# PIC18LF4620 register map
Vendor: Microchip
Architecture 18xxxx. Special function registers and configuration words.
Registers are 8-bit, read-write, no defined reset value unless marked. A register's access mark holds for its fields unless they carry their own. Addresses are absolute, and some are shared; only a register's first bit layout is shown; lines under a group give offsets from that group; [hi:lo] are bit positions; {n}, {i} and the like mark numbered series; 'fields as' and 'values as' point back to an identical list; <NAME> marks a mode.

## Further device data
pins=1: MCLR/VPP/RE3; 2: RA0/AN0; 3: RA1/AN1; 4: RA2/AN2/VREF-/CVREF; 5: RA3/AN3/VREF+; 6: RA4/T0CKI/C1OUT; 7: RA5/AN4/SS/HLVDIN/C2OUT; 8: RE0/RD/AN5; 9: RE1/WR/AN6; 10: RE2/CS/AN7; 11: VDD; 12: VSS; 13: OSC1/CLKI/RA7; 14: OSC2/CLKO/RA6; 15: RC0/T1OSO/T13CKI; 16: RC1/T1OSI/CCP2; 17: RC2/CCP1/P1A; 18: RC3/SCK/SCL; 19: RD0/PSP0; 20: RD1/PSP1; 21: RD2/PSP2; 22: RD3/PSP3; 23: RC4/SDI/SDA; 24: RC5/SDO; 25: RC6/TX/CK; 26: RC7/RX/DT; 27: RD4/PSP4; 28: RD5/PSP5/P1B; 29: RD6/PSP6/P1C; 30: RD7/PSP7/P1D; 31: RB0/INT0/FLT0/AN12; 32: RB1/INT1/AN10; 33: RB2/INT2/AN8; 34: RB3/AN9/CCP2; 35: RB4/KBI0/AN11; 36: RB5/KBI1/PGM; 37: RB6/KBI2/PGC; 38: RB7/KBI3/PGD

## SFR
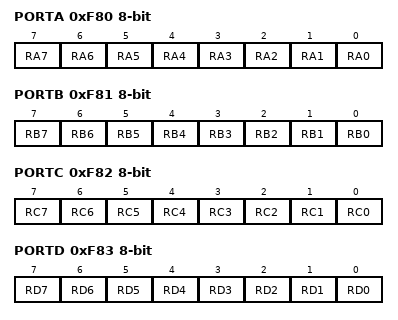
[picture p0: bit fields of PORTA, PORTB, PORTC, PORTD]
0xF80 PORTA — (power-on value xx0x0000)
  [n] RA{n} (n=0..7)
0xF81 PORTB — (power-on value xxxxxxxx)
  [n] RB{n} (n=0..7)
0xF82 PORTC — (power-on value xxxxxxxx)
  [n] RC{n} (n=0..7)
0xF83 PORTD — (power-on value xxxxxxxx)
  [n] RD{n} (n=0..7)
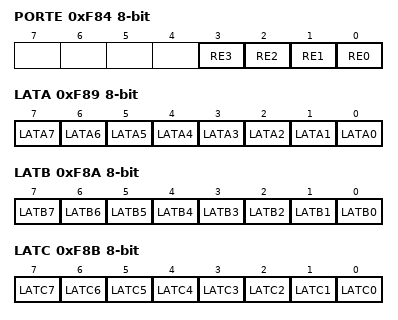
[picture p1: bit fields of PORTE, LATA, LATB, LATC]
0xF84 PORTE — (power-on value ----xxxx)
  [3] RE3 ro, [2] RE2, [1] RE1, [0] RE0
0xF89 LATA — (power-on value xxxxxxxx)
  [n] LATA{n} (n=0..7)
0xF8A LATB — (power-on value xxxxxxxx)
  [n] LATB{n} (n=0..7)
0xF8B LATC — (power-on value xxxxxxxx)
  [n] LATC{n} (n=0..7)
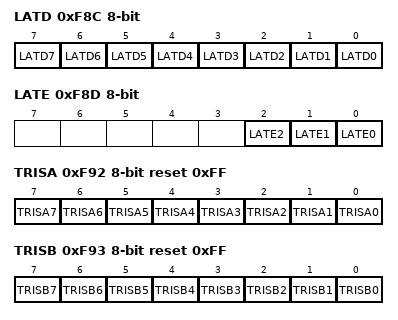
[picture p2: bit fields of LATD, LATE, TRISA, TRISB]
0xF8C LATD — (power-on value xxxxxxxx)
  [n] LATD{n} (n=0..7)
0xF8D LATE — (power-on value -----xxx)
  [2] LATE2, [1] LATE1, [0] LATE0
0xF92 TRISA reset 0xFF
  [n] TRISA{n} (n=0..7)
0xF93 TRISB reset 0xFF
  [n] TRISB{n} (n=0..7)
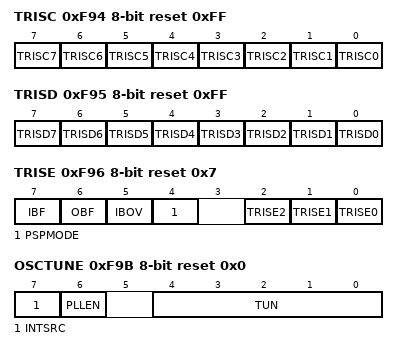
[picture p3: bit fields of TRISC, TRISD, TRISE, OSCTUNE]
0xF94 TRISC reset 0xFF
  [n] TRISC{n} (n=0..7)
0xF95 TRISD reset 0xFF
  [n] TRISD{n} (n=0..7)
0xF96 TRISE reset 0x7
  [7] IBF, [6] OBF, [5] IBOV, [4] PSPMODE, [2] TRISE2, [1] TRISE1, [0] TRISE0
0xF9B OSCTUNE reset 0x0
  [7] INTSRC, [6] PLLEN, [4:0] TUN
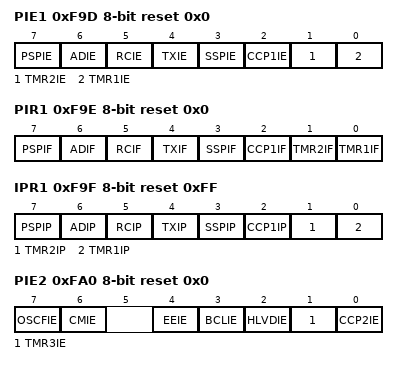
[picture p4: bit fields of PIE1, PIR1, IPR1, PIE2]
0xF9D PIE1 reset 0x0
  [7] PSPIE, [6] ADIE, [5] RCIE, [4] TXIE, [3] SSPIE, [2] CCP1IE, [1] TMR2IE, [0] TMR1IE
0xF9E PIR1 reset 0x0
  [7] PSPIF, [6] ADIF, [5] RCIF ro, [4] TXIF ro, [3] SSPIF, [2] CCP1IF, [1] TMR2IF, [0] TMR1IF
0xF9F IPR1 reset 0xFF
  [7] PSPIP, [6] ADIP, [5] RCIP, [4] TXIP, [3] SSPIP, [2] CCP1IP, [1] TMR2IP, [0] TMR1IP
0xFA0 PIE2 reset 0x0
  [7] OSCFIE, [6] CMIE, [4] EEIE, [3] BCLIE, [2] HLVDIE, [1] TMR3IE, [0] CCP2IE
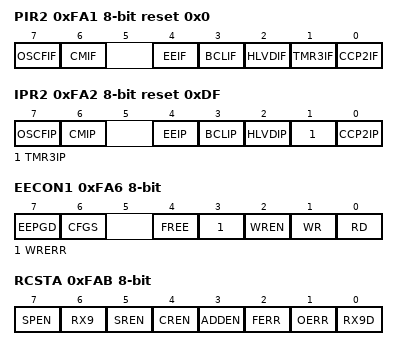
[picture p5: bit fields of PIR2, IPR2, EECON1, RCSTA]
0xFA1 PIR2 reset 0x0
  [7] OSCFIF, [6] CMIF, [4] EEIF, [3] BCLIF, [2] HLVDIF, [1] TMR3IF, [0] CCP2IF
0xFA2 IPR2 reset 0xDF
  [7] OSCFIP, [6] CMIP, [4] EEIP, [3] BCLIP, [2] HLVDIP, [1] TMR3IP, [0] CCP2IP
0xFA6 EECON1 — (power-on value xx-0x000)
  [7] EEPGD
  [6] CFGS
  [4] FREE
  [3] WRERR
  [2] WREN
  [1] WR — (can only be set)
  [0] RD — (can only be set)
0xFA7 EECON2 wo
0xFA8 EEDATA reset 0x0
0xFA9 EEADR reset 0x0
0xFAA EEADRH reset 0x0
  [1:0] EEADRH
0xFAB RCSTA — (power-on value 0000000x)
  [7] SPEN, [6] RX9, [5] SREN, [4] CREN, [3] ADDEN, [2] FERR ro, [1] OERR ro, [0] RX9D ro
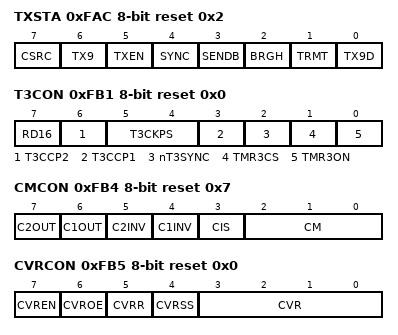
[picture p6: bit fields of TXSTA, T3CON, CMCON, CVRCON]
0xFAC TXSTA reset 0x2
  [7] CSRC, [6] TX9, [5] TXEN, [4] SYNC, [3] SENDB, [2] BRGH, [1] TRMT ro, [0] TX9D
0xFAD TXREG wo reset 0x0
0xFAE RCREG ro reset 0x0
0xFAF SPBRG reset 0x0
0xFB0 SPBRGH reset 0x0
0xFB1 T3CON reset 0x0
  [7] RD16, [6] T3CCP2, [5:4] T3CKPS, [3] T3CCP1, [2] nT3SYNC, [1] TMR3CS, [0] TMR3ON
0xFB2 TMR3L — (power-on value xxxxxxxx)
0xFB3 TMR3H — (power-on value xxxxxxxx)
0xFB4 CMCON reset 0x7
  [7] C2OUT ro, [6] C1OUT ro, [5] C2INV, [4] C1INV, [3] CIS, [2:0] CM
0xFB5 CVRCON reset 0x0
  [7] CVREN, [6] CVROE, [5] CVRR, [4] CVRSS, [3:0] CVR
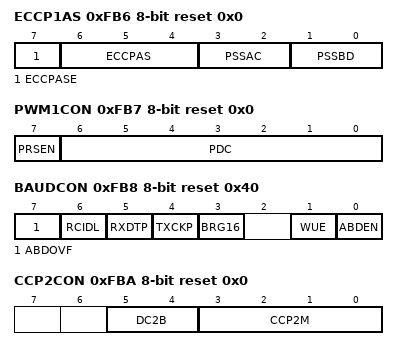
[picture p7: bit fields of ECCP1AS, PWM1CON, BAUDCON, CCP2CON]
0xFB6 ECCP1AS reset 0x0
  [7] ECCPASE, [6:4] ECCPAS, [3:2] PSSAC, [1:0] PSSBD
0xFB7 PWM1CON reset 0x0
  [7] PRSEN, [6:0] PDC
0xFB8 BAUDCON reset 0x40
  [7] ABDOVF — (can only be cleared)
  [6] RCIDL ro
  [5] RXDTP
  [4] TXCKP
  [3] BRG16
  [1] WUE
  [0] ABDEN
0xFBA CCP2CON reset 0x0
  [5:4] DC2B, [3:0] CCP2M
0xFBB CCPR2L — (power-on value xxxxxxxx)
0xFBC CCPR2H — (power-on value xxxxxxxx)
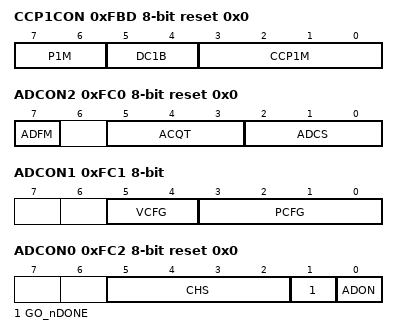
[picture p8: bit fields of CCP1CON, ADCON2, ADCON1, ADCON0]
0xFBD CCP1CON reset 0x0
  [7:6] P1M, [5:4] DC1B, [3:0] CCP1M
0xFBE CCPR1L — (power-on value xxxxxxxx)
0xFBF CCPR1H — (power-on value xxxxxxxx)
0xFC0 ADCON2 reset 0x0
  [7] ADFM, [5:3] ACQT, [2:0] ADCS
0xFC1 ADCON1 — (power-on value --00qqqq)
  [5:4] VCFG, [3:0] PCFG
0xFC2 ADCON0 reset 0x0
  [5:2] CHS, [1] GO_nDONE, [0] ADON
0xFC3 ADRESL — (power-on value xxxxxxxx)
0xFC4 ADRESH — (power-on value xxxxxxxx)
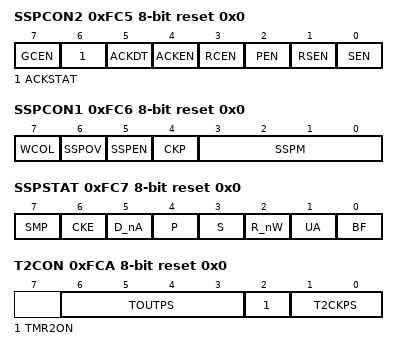
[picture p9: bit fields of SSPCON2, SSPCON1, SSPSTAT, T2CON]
0xFC5 SSPCON2 reset 0x0
  [7] GCEN, [6] ACKSTAT, [5] ACKDT, [4] ACKEN, [3] RCEN, [2] PEN, [1] RSEN, [0] SEN
0xFC6 SSPCON1 reset 0x0
  [7] WCOL, [6] SSPOV, [5] SSPEN, [4] CKP, [3:0] SSPM
0xFC7 SSPSTAT reset 0x0
  [7] SMP, [6] CKE, [5] D_nA, [4] P, [3] S, [2] R_nW, [1] UA, [0] BF
0xFC8 SSPADD reset 0x0
0xFC9 SSPBUF — (power-on value xxxxxxxx)
0xFCA T2CON reset 0x0
  [6:3] TOUTPS, [2] TMR2ON, [1:0] T2CKPS
0xFCB PR2 reset 0xFF
0xFCC TMR2 reset 0x0
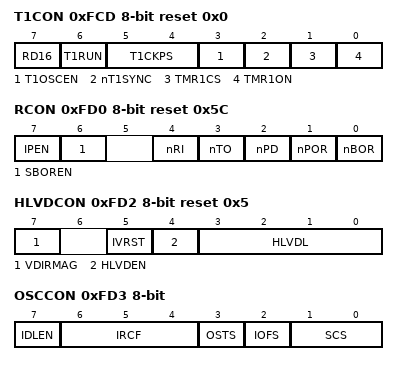
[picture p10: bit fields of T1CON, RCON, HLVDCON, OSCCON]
0xFCD T1CON reset 0x0
  [7] RD16, [6] T1RUN ro, [5:4] T1CKPS, [3] T1OSCEN, [2] nT1SYNC, [1] TMR1CS, [0] TMR1ON
0xFCE TMR1L — (power-on value xxxxxxxx)
0xFCF TMR1H — (power-on value xxxxxxxx)
0xFD0 RCON reset 0x5C
  [7] IPEN, [6] SBOREN, [4] nRI, [3] nTO, [2] nPD, [1] nPOR, [0] nBOR
0xFD1 WDTCON reset 0x0
  [0] SWDTEN
0xFD2 HLVDCON reset 0x5
  [7] VDIRMAG, [5] IVRST ro, [4] HLVDEN, [3:0] HLVDL
0xFD3 OSCCON — (power-on value 0100q000)
  [7] IDLEN, [6:4] IRCF, [3] OSTS ro, [2] IOFS, [1:0] SCS
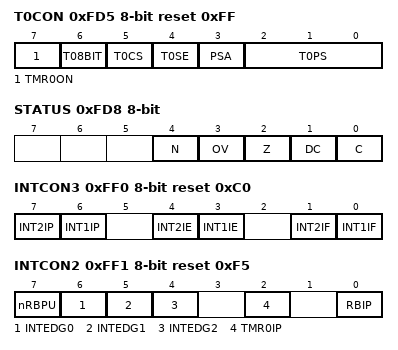
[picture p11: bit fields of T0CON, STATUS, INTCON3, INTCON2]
0xFD5 T0CON reset 0xFF
  [7] TMR0ON, [6] T08BIT, [5] T0CS, [4] T0SE, [3] PSA, [2:0] T0PS
0xFD6 TMR0L — (power-on value xxxxxxxx)
0xFD7 TMR0H reset 0x0
0xFD8 STATUS — (power-on value ---xxxxx)
  [4] N, [3] OV, [2] Z, [1] DC, [0] C
0xFD9 FSR2L — (power-on value xxxxxxxx)
0xFDA FSR2H reset 0x0
  [3:0] FSR2H
0xFDB PLUSW2 access not given
0xFDC PREINC2 access not given
0xFDD POSTDEC2 access not given
0xFDE POSTINC2 access not given
0xFDF INDF2 access not given
0xFE0 BSR reset 0x0
  [3:0] BSR
0xFE1 FSR1L — (power-on value xxxxxxxx)
0xFE2 FSR1H reset 0x0
  [3:0] FSR1H
0xFE3 PLUSW1 access not given
0xFE4 PREINC1 access not given
0xFE5 POSTDEC1 access not given
0xFE6 POSTINC1 access not given
0xFE7 INDF1 access not given
0xFE8 WREG — (power-on value xxxxxxxx)
0xFE9 FSR0L — (power-on value xxxxxxxx)
0xFEA FSR0H reset 0x0
  [3:0] FSR0H
0xFEB PLUSW0 access not given
0xFEC PREINC0 access not given
0xFED POSTDEC0 access not given
0xFEE POSTINC0 access not given
0xFEF INDF0 access not given
0xFF0 INTCON3 reset 0xC0
  [7] INT2IP, [6] INT1IP, [4] INT2IE, [3] INT1IE, [1] INT2IF, [0] INT1IF
0xFF1 INTCON2 reset 0xF5
  [7] nRBPU, [6] INTEDG0, [5] INTEDG1, [4] INTEDG2, [2] TMR0IP, [0] RBIP
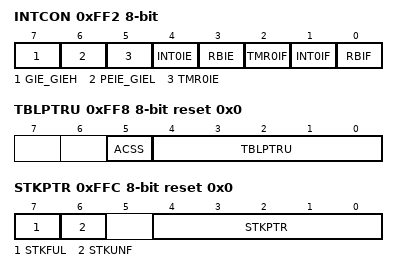
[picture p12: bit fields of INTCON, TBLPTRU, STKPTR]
0xFF2 INTCON — (power-on value 0000000x)
  [7] GIE_GIEH, [6] PEIE_GIEL, [5] TMR0IE, [4] INT0IE, [3] RBIE, [2] TMR0IF, [1] INT0IF, [0] RBIF
0xFF3 PRODL — (power-on value xxxxxxxx)
0xFF4 PRODH — (power-on value xxxxxxxx)
0xFF5 TABLAT reset 0x0
0xFF6 TBLPTRL reset 0x0
0xFF7 TBLPTRH reset 0x0
0xFF8 TBLPTRU reset 0x0
  [5] ACSS, [4:0] TBLPTRU
0xFF9 PCL reset 0x0
0xFFA PCLATH reset 0x0
  [7:0] PCH
0xFFB PCLATU reset 0x0
  [4:0] PCU
0xFFC STKPTR reset 0x0
  [7] STKFUL — (can only be cleared)
  [6] STKUNF — (can only be cleared)
  [4:0] STKPTR
0xFFD TOSL reset 0x0
0xFFE TOSH reset 0x0
0xFFF TOSU reset 0x0
  [4:0] TOSU
